# cbass_ipcss_CBASS_GLB_45B01000h register map
Vendor: Texas Instruments
Peripheral module from a debugger description file (folder am62D).
Registers are 32-bit, read-only, reset 0x0 unless marked. A register's access mark holds for its fields unless they carry their own. Offsets are as the file gives them; lines under a group give offsets from that group; [hi:lo] are bit positions; {n}, {i} and the like mark numbered series; 'fields as' and 'values as' point back to an identical list; <NAME> marks a mode.

## cbass_glb
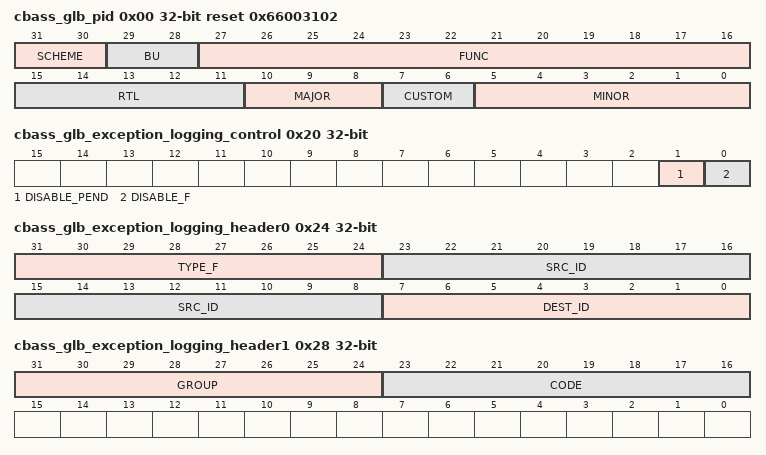
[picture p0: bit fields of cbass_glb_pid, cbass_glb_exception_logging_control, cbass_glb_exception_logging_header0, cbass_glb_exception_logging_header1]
0x00 cbass_glb_pid reset 0x66003102 — The Revision Register contains the major and minor revisions for the module.
  [31:30] SCHEME — PID register scheme Reset Source: domain_default_rst_mod_g_rst_n
  [29:28] BU — Business Unit: 10 = Processors Reset Source: domain_default_rst_mod_g_rst_n
  [27:16] FUNC — Module ID Reset Source: domain_default_rst_mod_g_rst_n
  [15:11] RTL — RTL revision. Will vary depending on release. Reset Source: domain_default_rst_mod_g_rst_n
  [10:8] MAJOR — Major revision Reset Source: domain_default_rst_mod_g_rst_n
  [7:6] CUSTOM — Custom Reset Source: domain_default_rst_mod_g_rst_n
  [5:0] MINOR — Minor revision Reset Source: domain_default_rst_mod_g_rst_n
0x04 cbass_glb_destination_id rw — The Destination ID Register defines the destination ID value for error messages.
  [7:0] DEST_ID — The destination ID. Reset Source: domain_default_rst_mod_g_rst_n
0x20 cbass_glb_exception_logging_control rw — The Exception Logging Control Register controls the exception logging.
  [1] DISABLE_PEND — Disables logging pending when set. Reset Source: domain_default_rst_mod_g_rst_n
  [0] DISABLE_F — Disables logging when set. Reset Source: domain_default_rst_mod_g_rst_n
0x24 cbass_glb_exception_logging_header0 — The Exception Logging Header 0 Register contains the first word of the header.
  [31:24] TYPE_F — Type. Reset Source: domain_default_rst_mod_g_rst_n
  [23:8] SRC_ID — Source ID. Reset Source: domain_default_rst_mod_g_rst_n
  [7:0] DEST_ID — Destination ID. Reset Source: domain_default_rst_mod_g_rst_n
0x28 cbass_glb_exception_logging_header1 — The Exception Logging Header 1 Register contains the second word of the header.
  [31:24] GROUP — Group. Reset Source: domain_default_rst_mod_g_rst_n
  [23:16] CODE — Code. Reset Source: domain_default_rst_mod_g_rst_n
0x2C cbass_glb_exception_logging_data0 — The Exception Logging Data 0 Register contains the first word of the data.
  [31:0] ADDR_L — Address lower 32 bits. Reset Source: domain_default_rst_mod_g_rst_n
0x30 cbass_glb_exception_logging_data1 — The Exception Logging Data 1 Register contains the second word of the data.
  [15:0] ADDR_H — Address upper 16 bits. Reset Source: domain_default_rst_mod_g_rst_n
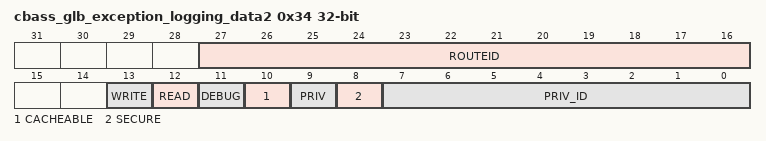
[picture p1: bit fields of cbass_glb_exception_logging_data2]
0x34 cbass_glb_exception_logging_data2 — The Exception Logging Data 2 Register contains the third word of the data.
  [27:16] ROUTEID — Route ID. Reset Source: domain_default_rst_mod_g_rst_n
  [13] WRITE — Write. Reset Source: domain_default_rst_mod_g_rst_n
  [12] READ — Read. Reset Source: domain_default_rst_mod_g_rst_n
  [11] DEBUG — Debug. Reset Source: domain_default_rst_mod_g_rst_n
  [10] CACHEABLE — Cacheable. Reset Source: domain_default_rst_mod_g_rst_n
  [9] PRIV — Priv. Reset Source: domain_default_rst_mod_g_rst_n
  [8] SECURE — Secure. Reset Source: domain_default_rst_mod_g_rst_n
  [7:0] PRIV_ID — Priv ID. Reset Source: domain_default_rst_mod_g_rst_n
0x38 cbass_glb_exception_logging_data3 — The Exception Logging Data 3 Register contains the fourth word of the data.
  [9:0] BYTECNT — Byte count. Reset Source: domain_default_rst_mod_g_rst_n
0x40 cbass_glb_exception_pend_set access not given — The Exception Logging Pending Set Register allows to set the pend signal.
  [0] PEND_SET — Write a 1 to set the exception pend signal. Reset Source: domain_default_rst_mod_g_rst_n (access R/W1TS)
0x44 cbass_glb_exception_pend_clear access not given — The Exception Logging Pending Clear Register allows to clear the pend signal.
  [0] PEND_CLR — Write a 1 to clear the exception pend signal. Reset Source: domain_default_rst_mod_g_rst_n (access R/W1TC)
